# SGPIO2 register map
Registers from a debugger description file.
Registers are 32-bit, access not given, no defined reset value unless marked. A register's access mark holds for its fields unless they carry their own. Addresses are absolute; registers are grouped by the start of their names; lines under a group give offsets from that group; [hi:lo] are bit positions; {n}, {i} and the like mark numbered series; 'fields as' and 'values as' point back to an identical list; <NAME> marks a mode.

## SGPIO2
0x4006E000 SGPIO2/Input ro
  [31:0] Input
0x4006E004 SGPIO2/Output
  [31:0] Output
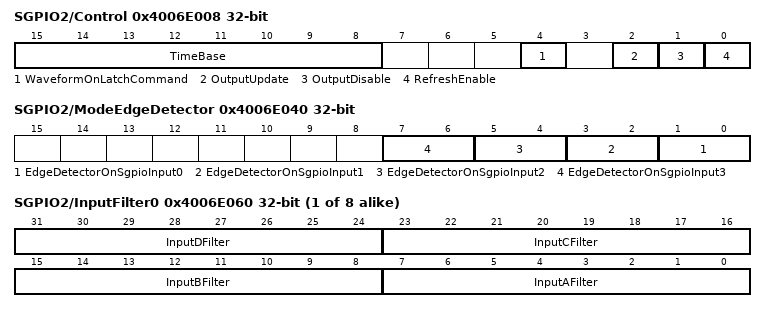
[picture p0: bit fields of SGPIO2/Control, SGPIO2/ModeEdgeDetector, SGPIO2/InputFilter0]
0x4006E008 SGPIO2/Control
  [15:8] TimeBase, [4] WaveformOnLatchCommand, [2] OutputUpdate, [1] OutputDisable, [0] RefreshEnable
0x4006E040 SGPIO2/ModeEdgeDetector
  [2n+1:2n] EdgeDetectorOnSgpioInput{n} (n=0..3)
0x4006E044 SGPIO2/StatusInt0
  [3:0] StatusInt0
0x4006E048 SGPIO2/StatusInt1
  [3:0] StatusInt1
0x4006E04C SGPIO2/MaskInt
  [3:0] MaskInt
0x4006E050 SGPIO2/ClearInt
  [3:0] ClearInt
0x4006E054 SGPIO2/InputUpdate
  [31:0] InputUpdate
{0x4006E060+4i} SGPIO2/InputFilter{i} (i=0..7)
  [31:24] InputDFilter, [23:16] InputCFilter, [15:8] InputBFilter, [7:0] InputAFilter
